# NUC2201AE_v1 register map
File version: 1.0
Registers are 32-bit, read-write, reset 0x0 unless marked. A register's access mark holds for its fields unless they carry their own. Offsets are from the block's base; [hi:lo] are bit positions; {n}, {i} and the like mark numbered series.

## USBD — USB Register Map
Base 0x40060000
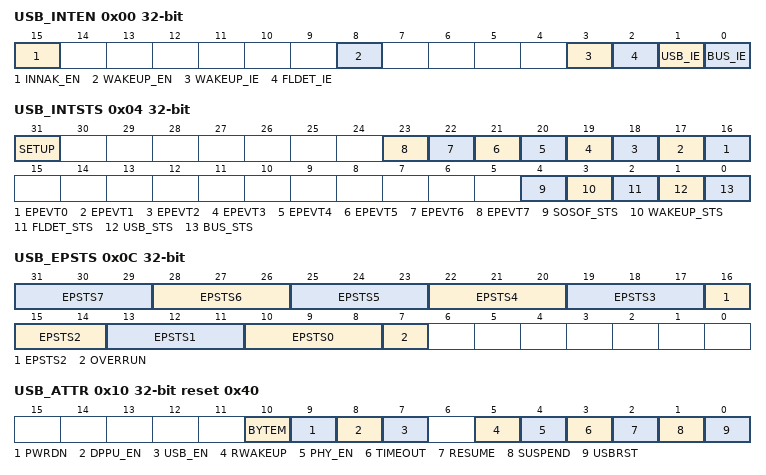
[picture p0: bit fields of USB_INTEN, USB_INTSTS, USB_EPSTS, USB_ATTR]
0x00 USB_INTEN — USB Interrupt Enable Register
  [15] INNAK_EN — Active NAK Function And Its Status In IN Token
    0=When device responds NAK after receiving IN token, IN NAK status will not be updated to USBD_EPSTS register, so that the USB interrupt event will not be asserted; 1=IN NAK status will be updated to USBD_EPSTS register and the USB interrupt event will be asserted, when the device responds NAK after receiving IN token
  [8] WAKEUP_EN — Wake-Up Function Enable Bit
    0=USB wake-up function Disabled; 1=USB wake-up function Enabled
  [3] WAKEUP_IE — USB Wake-Up Interrupt Enable Bit
    0=Wake-up Interrupt Disabled; 1=Wake-up Interrupt Enabled
  [2] FLDET_IE — Floating Detection Interrupt Enable Bit
    0=Floating detection Interrupt Disabled; 1=Floating detection Interrupt Enabled
  [1] USB_IE — USB Event Interrupt Enable Bit
    0=USB event interrupt Disabled; 1=USB event interrupt Enabled
  [0] BUS_IE — Bus Event Interrupt Enable Bit
    0=BUS event interrupt Disabled; 1=BUS event interrupt Enabled
0x04 USB_INTSTS — USB Interrupt Event Status Register
  [31] SETUP — Setup Event Status
    0=No Setup event; 1=SETUP event occurred, cleared by write 1 to USB_INTSTS[31]
  [n+16] EPEVT{n} (n=0..7) — Endpoint {n}'s USB Event Status
    0=No event occurred on endpoint {n}; 1=USB event occurred on Endpoint {n}, check USB_EPSTS[{3n+10}:{3n+8}] to know which kind of USB event was occurred, cleared by write 1 to USB_INTSTS[{n+16}] or USB_INTSTS[1]
  [4] SOSOF_STS — Start of Frame Interrupt Status
    0=SOF event does not occur; 1=SOF event occurred, cleared by write 1 to USBD_INTSTS[4]
  [3] WAKEUP_STS — Wake-Up Interrupt Status
    0=No Wake-up event occurred; 1=Wake-up event occurred, cleared by write 1 to USB_INTSTS[3]
  [2] FLDET_STS — Floating Detection Interrupt Status
    0=There is not attached/detached event in the USB; 1=There is attached/detached event in the USB bus and it is cleared by write 1 to USB_INTSTS[2]
  [1] USB_STS — USB Event Interrupt Status. The USB event includes the SETUP Token, IN Token, OUT ACK, ISO IN, or ISO OUT events in the bus.
    0=No USB event occurred; 1=USB event occurred, check EPSTS0~7 to know which kind of USB event occurred. Cleared by write 1 to USB_INTSTS[1] or EPEVT0~7 and SETUP (USB_INTSTS[31])
  [0] BUS_STS — BUS Interrupt Status. The BUS event means that there is one of the suspense or the resume function in the bus.
    0=No BUS event occurred; 1=Bus event occurred; check USB_ATTR[3:0] to know which kind of bus event was occurred, cleared by write 1 to USB_INTSTS[0]
0x08 USB_FADDR — USB Device Function Address Register
  [6:0] FADDR — USB Device Function Address
0x0C USB_EPSTS ro — USB Endpoint Status Register
  [3n+10:3n+8] EPSTS{n} (n=0..7) — Endpoint {n} Bus Status. These bits are used to indicate the current status of this endpoint
    0=In ACK; 1=In NAK; 2=Out Packet Data0 ACK; 3=Setup ACK; 6=Out Packet Data1 ACK; 7=Isochronous transfer end
  [7] OVERRUN — Overrun. It indicates that the received data is over the maximum payload number or not.
    0=No overrun; 1=Out Data is more than the Max Payload in MXPLD register or the Setup Data is more than 8 Bytes
0x10 USB_ATTR reset 0x40 — USB Bus Status and Attribution Register
  [10] BYTEM — CPU Access USB SRAM Size Mode Selection
    0=Word mode: The size of the transfer from CPU to USB SRAM can be Word only; 1=Byte mode: The size of the transfer from CPU to USB SRAM can be Byte only
  [9] PWRDN — Power-Down PHY Transceiver, Low Active
    0=Power-down related circuit of PHY transceiver; 1=Turn-on related circuit of PHY transceiver
  [8] DPPU_EN — Pull-Up Resistor On USB_D+ Enable Bit
    0=Pull-up resistor in USB_D+ pin Disabled; 1=Pull-up resistor in USB_D+ pin Enabled
  [7] USB_EN — USB Controller Enable Bit
    0=USB Controller Disabled; 1=USB Controller Enabled
  [5] RWAKEUP — Remote Wake-Up
    0=Release the USB bus from K state; 1=Force USB bus to K (USB_D+ low, USB_D- high) state, used for remote wake-up
  [4] PHY_EN — PHY Transceiver Function Enable Bit
    0=PHY transceiver function Disabled; 1=PHY transceiver function Enabled
  [3] TIMEOUT — Time-Out Status. Note: This bit is read only.
    0=No time-out; 1=No Bus response more than 18 bits time
  [2] RESUME — Resume Status. Note: This bit is read only.
    0=No bus resume; 1=Resume from suspend
  [1] SUSPEND — Suspend Status. Note: This bit is read only.
    0=Bus no suspend; 1=Bus idle more than 3ms, either cable is plugged off or host is sleeping
  [0] USBRST — USB Reset Status. Note: This bit is read only.
    0=Bus no reset; 1=Bus reset when SE0 (single-ended 0) is presented more than 2.5us
0x14 USB_FLDET ro — USB Floating Detection Register
  [0] FLDET — Device Floating Detected
    0=Controller is not attached into the USB host; 1=Controller is attached into the BUS
0x18 USB_STBUFSEG — Setup Token Buffer Segmentation Register
  [8:3] STBUFSEG — Setup Token Buffer Segmentation. It is used to indicate the offset address for the SETUP token with the USB Device SRAM starting address The effective starting address is. USB_SRAM address + {STBUFSEG[8:3], 3'b000} Note: It is used for SETUP token only.
0x8C USBD_FN ro (reset mask 0xFFFFF000) — USB Frame Number Register
  [10:0] FN — Frame Number. These bits contain the 11-bits frame number in the last received SOF packet.
0x90 USB_DRVSE0 reset 0x1 — USB Drive SE0 Control Register
  [0] DRVSE0 — Drive Single Ended Zero In USB Bus. The Single Ended Zero (SE0) is when both lines (USB_D+ and USB_D-) are being pulled low.
    0=None; 1=Force USB PHY transceiver to drive SE0
{0x500+0x10*i} USB_BUFSEG{i} (i=0..7) — Endpoint {i} Buffer Segmentation Register
  [8:3] BUFSEG — Endpoint Buffer Segmentation. It is used to indicate the offset address for each endpoint with the USB SRAM starting address The effective starting address of the endpoint is. USB_SRAM address + { BUFSEG[8:3], 3'b000} Refer to the section 5.4.4.7 for the endpoint SRAM structure and its description.
{0x504+0x10*i} USB_MXPLD{i} (i=0..7) — Endpoint {i} Maximal Payload Register
  [8:0] MXPLD — Maximal Payload. Define the data length which is transmitted to host (IN token) or the actual data length which is received from the host (OUT token). It also used to indicate that the endpoint is ready to be transmitted in IN token or received in OUT token. (1) When the register is written by CPU, For IN token, the value of MXPLD is used to define the data length to be transmitted and indicate the data buffer is ready. For OUT token, it means that the controller is ready to receive data from the host and the value of MXPLD is the maximal data length comes from host. (2) When the register is read by CPU, For IN token, the value of MXPLD is indicated by the data length be transmitted to host. For OUT token, the value of MXPLD is indicated the actual data length receiving from host. Note: Once MXPLD is written, the data packets will be transmitted/received immediately after IN/OUT token arrived.
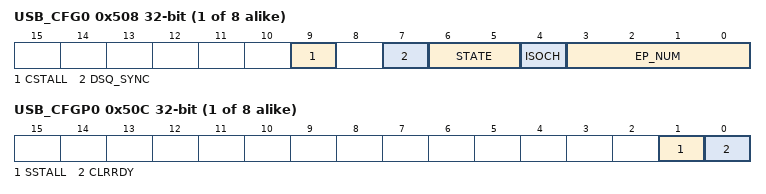
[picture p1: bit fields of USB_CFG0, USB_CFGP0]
{0x508+0x10*i} USB_CFG{i} (i=0..7) — Endpoint {i} Configuration Register
  [9] CSTALL — Clear STALL Response
    0=Disable the device to clear the STALL handshake in setup stage; 1=Clear the device to response STALL handshake in setup stage
  [7] DSQ_SYNC — Data Sequence Synchronization. Note: It is used to specify the DATA0 or DATA1 PID in the following IN token transaction. Hardware will toggle automatically in IN token base on the bit.
    0=DATA0 PID; 1=DATA1 PID
  [6:5] STATE — Endpoint STATE
    0=Endpoint is Disabled; 1=Out endpoint; 2=IN endpoint; 3=Undefined
  [4] ISOCH — Isochronous Endpoint. This bit is used to set the endpoint as Isochronous endpoint, no handshake.
    0=No Isochronous endpoint; 1=Isochronous endpoint
  [3:0] EP_NUM — Endpoint Number. These bits are used to define the endpoint number of the current endpoint.
{0x50C+0x10*i} USB_CFGP{i} (i=0..7) — Endpoint {i} Set Stall and Clear In/Out Ready Control Register
  [1] SSTALL — Set STALL
    0=Disable the device to response STALL; 1=Set the device to respond STALL automatically
  [0] CLRRDY — Clear Ready. When the USB_MXPLD register is set by user, it means that the endpoint is ready to transmit or receive data. If the user wants to disable this transaction before the transaction start, users can set this bit to 1 to turn it off and it will be cleared to 0 automatically. For IN token, write '1' to clear the IN token had ready to transmit the data to USB. For OUT token, write '1' to clear the OUT token had ready to receive the data from USB. This bit is write 1 only and is always 0 when it is read back.
